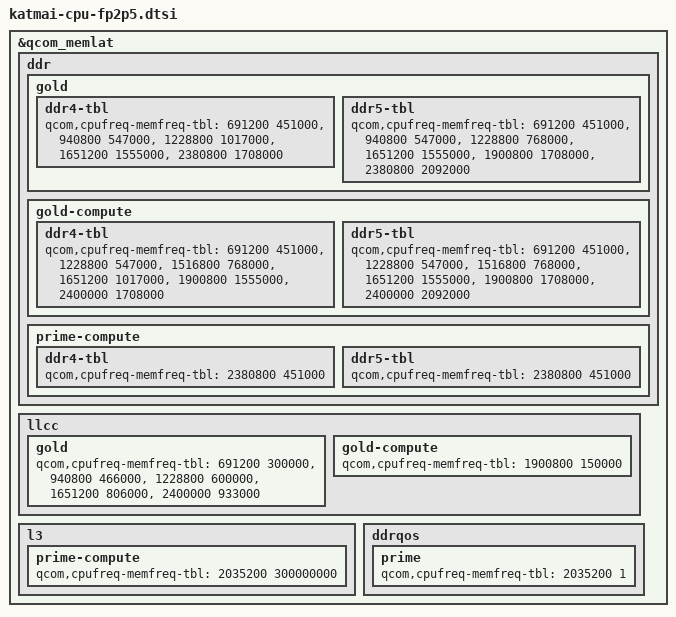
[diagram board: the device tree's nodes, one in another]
// SPDX-License-Identifier: BSD-3-Clause
/*
 * Copyright (c) 2025 Qualcomm Innovation Center, Inc. All rights reserved.
 */

#include "katmai-cpu-fp2.dtsi"

&qcom_memlat {
	ddr {
		gold {
			ddr4-tbl {
				qcom,cpufreq-memfreq-tbl =
					<  691200  451000 >,
					<  940800  547000 >,
					< 1228800 1017000 >,
					< 1651200 1555000 >,
					< 2380800 1708000 >;
			};

			ddr5-tbl {
				qcom,cpufreq-memfreq-tbl =
					<  691200  451000 >,
					<  940800  547000 >,
					< 1228800  768000 >,
					< 1651200 1555000 >,
					< 1900800 1708000 >,
					< 2380800 2092000 >;
			};
		};

		gold-compute {
			ddr4-tbl {
				qcom,cpufreq-memfreq-tbl =
					<  691200  451000 >,
					< 1228800  547000 >,
					< 1516800  768000 >,
					< 1651200 1017000 >,
					< 1900800 1555000 >,
					< 2400000 1708000 >;
			};

			ddr5-tbl {
				qcom,cpufreq-memfreq-tbl =
					<  691200  451000 >,
					< 1228800  547000 >,
					< 1516800  768000 >,
					< 1651200 1555000 >,
					< 1900800 1708000 >,
					< 2400000 2092000 >;
			};
		};

		prime-compute {
			ddr4-tbl {
				qcom,cpufreq-memfreq-tbl =
					< 2380800  451000 >;
			};

			ddr5-tbl {
				qcom,cpufreq-memfreq-tbl =
					< 2380800  451000 >;
			};
		};
	};

	llcc {
		gold {
			qcom,cpufreq-memfreq-tbl =
				<  691200   300000 >,
				<  940800   466000 >,
				< 1228800   600000 >,
				< 1651200   806000 >,
				< 2400000   933000 >;
		};

		gold-compute {
			qcom,cpufreq-memfreq-tbl =
				< 1900800  150000 >;
		};
	};

	l3 {
		prime-compute {
			qcom,cpufreq-memfreq-tbl =
				< 2035200  300000000 >;
		};
	};

	ddrqos {
		prime {
			qcom,cpufreq-memfreq-tbl =
				< 2035200 1 >;
		};
	};
};
